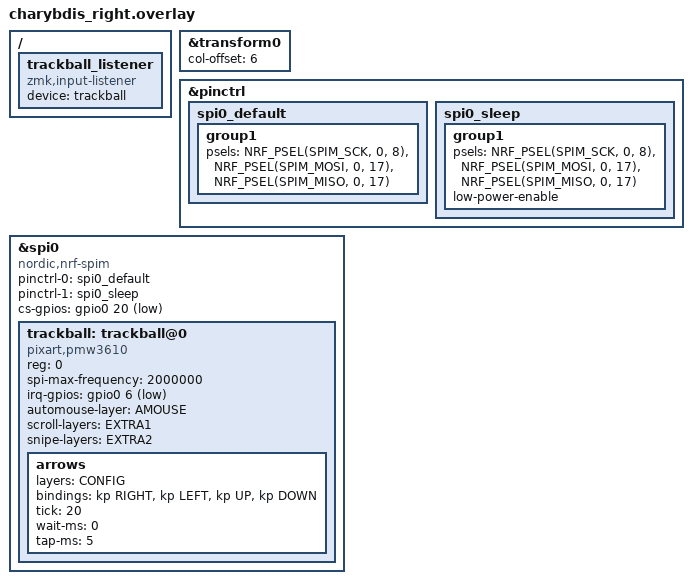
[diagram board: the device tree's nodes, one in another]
#include "charybdis.dtsi"
#include <dt-bindings/zmk/keys.h>

#define QWERTY 0
#define COLMAK 1
#define EXTRA1 2
#define EXTRA2 3
#define CONFIG 4
#define AMOUSE 5

&transform0 {
    col-offset = <6>;
};

&pinctrl {
    spi0_default: spi0_default {
        group1 {
            psels = <NRF_PSEL(SPIM_SCK,  0,  8)>,
                    <NRF_PSEL(SPIM_MOSI, 0, 17)>,
                    <NRF_PSEL(SPIM_MISO, 0, 17)>;
        };
    };
    spi0_sleep: spi0_sleep {
        group1 {
            psels = <NRF_PSEL(SPIM_SCK,  0,  8)>,
                    <NRF_PSEL(SPIM_MOSI, 0, 17)>,
                    <NRF_PSEL(SPIM_MISO, 0, 17)>;
            low-power-enable;
        };
    };
};

&spi0 {
    status = "okay";
    compatible = "nordic,nrf-spim";
    pinctrl-0 = <&spi0_default>;
    pinctrl-1 = <&spi0_sleep>;
    pinctrl-names = "default", "sleep";
    cs-gpios = <&gpio0 20 GPIO_ACTIVE_LOW>;

    trackball: trackball@0 {
        status = "okay";
        compatible = "pixart,pmw3610";
        reg = <0>;
        spi-max-frequency = <2000000>;
        irq-gpios = <&gpio0 6 (GPIO_ACTIVE_LOW | GPIO_PULL_UP)>;

        /* optional features */

        automouse-layer = <AMOUSE>;
        scroll-layers = <EXTRA1>;
        snipe-layers = <EXTRA2>;

        /* optional: ball action on specific layers */
        arrows {
            layers = <CONFIG>;
            bindings = <&kp RIGHT>, <&kp LEFT>, <&kp UP>, <&kp DOWN>;
            /* optional: ball action configuration */
            tick = <20>;
            wait-ms = <0>; 
            tap-ms = <5>;
        };
    };
};

/ {
  trackball_listener: trackball_listener {
    compatible = "zmk,input-listener";
    device = <&trackball>;
  };
};
